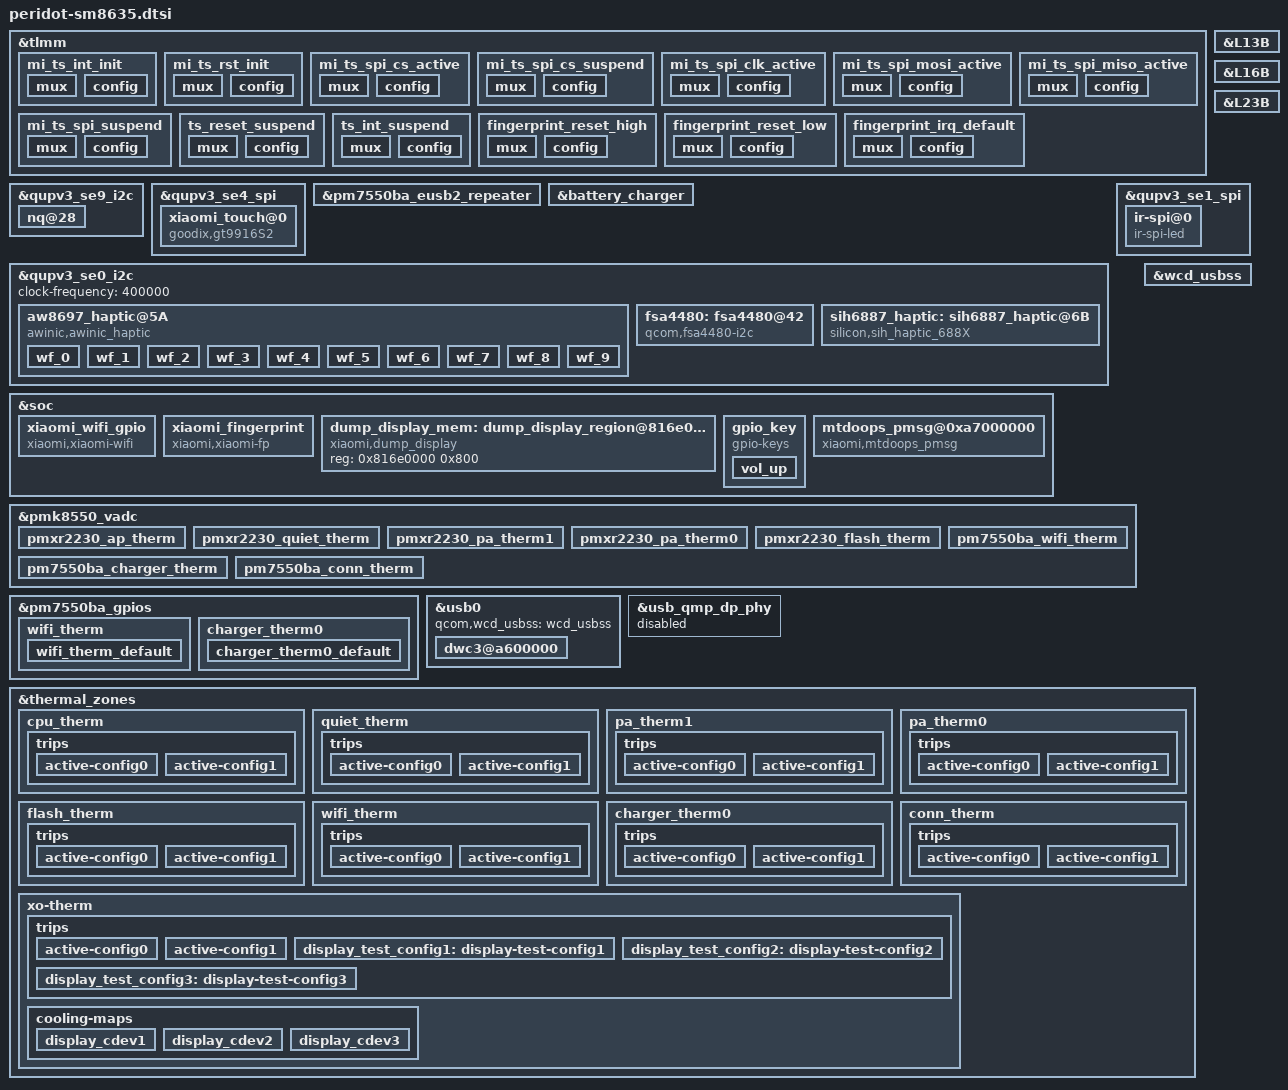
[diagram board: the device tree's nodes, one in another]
#include "cliffs-mtp.dtsi"
#include "cliffs-pm7550ba.dtsi"
#include "peridot-pinctrl.dtsi"

&tlmm {
	mi_ts_int_init: mi_ts_int_init {
		mux {
			pins = "gpio129";
			function = "gpio";
		};

		config {
			pins = "gpio129";
			input-enable;
			bias-disable;
		};
	};
	mi_ts_rst_init: mi_ts_rst_init {
		mux {
			pins = "gpio128";
			function = "gpio";
		};

		config {
			pins = "gpio128";
			drive-strength = <6>;
			bias-disable;
			output-low;
		};
	};

	mi_ts_spi_cs_active: mi_ts_spi_cs_active {
		mux {
			pins = "gpio19";
			function = "qup0_se4_l3";
		};

		config {
			pins = "gpio19";
			drive-strength = <6>;
			bias-disable;
		};
	};

    mi_ts_spi_cs_suspend: mi_ts_spi_cs_suspend {
		mux {
			pins = "gpio19";
			function = "gpio";
		};

		config {
			pins = "gpio19";
			drive-strength = <2>;
			bias-disable;
		};
	};

	mi_ts_spi_clk_active: mi_ts_spi_clk_active {
		mux {
			pins = "gpio18";
			function = "qup0_se4_l2";
		};
		config {
			pins = "gpio18";
			drive-strength = <6>;
			bias-disable;
		};
	};

	mi_ts_spi_mosi_active: mi_ts_spi_mosi_active {
		mux {
			pins = "gpio17";
			function = "qup0_se4_l1";
		};
		config {
			pins = "gpio17";
			drive-strength = <6>;
			bias-disable;
		};
	};


	mi_ts_spi_miso_active: mi_ts_spi_miso_active {
		mux {
			pins = "gpio16";
			function = "qup0_se4_l0";
		};
		config {
			pins = "gpio16";
			drive-strength = <6>;
			bias-disable;
		};
	};


	mi_ts_spi_suspend: mi_ts_spi_suspend {
		mux {
			pins = "gpio16", "gpio17", "gpio18";
			function = "gpio";
		};

		config {
			pins = "gpio16", "gpio17", "gpio18";
			drive-strength = <2>;
			bias-disable;
		};
	};

	ts_reset_suspend: ts_reset_suspend {
		mux {
			pins = "gpio128";
			function = "gpio";
		};

		config {
			pins = "gpio128";
			drive-strength = <6>;
			bias-disable;
		};
	};

	ts_int_suspend: ts_int_suspend {
		mux {
			pins = "gpio129";
			function = "gpio";
		};

		config {
			pins = "gpio129";
			input-enable;
			bias-disable;
		};
	};

    /* FP_RESET_HIGH, state device active*/
    fingerprint_reset_high: fingerprint_reset_high {
        mux {
                pins = "gpio55";
                function = "gpio";
        };
        config {
                pins = "gpio55";
                drive-strength = <2>;
                bias-disable;
                output-high;
        };
    };
    /* FP_RESET_LOW */
    fingerprint_reset_low: fingerprint_reset_low {
        mux {
                pins = "gpio55";
                function = "gpio";
        };
        config {
                pins = "gpio55";
                drive-strength = <2>;
                bias-disable;
                output-low;
        };
    };
    /* FP_INT_N */
    fingerprint_irq_default: fingerprint_irq_default {
        mux {
                pins = "gpio117";
                function = "gpio";
        };
        config {
                pins = "gpio117";
                drive-strength = <2>;
                bias-pull-down;
        };
    };
};

&L13B {
	regulator-min-microvolt = <3300000>;
	regulator-max-microvolt = <3300000>;
	qcom,init-voltage = <3300000>;
};

&L16B {
	regulator-boot-on;
	regulator-always-on;
	regulator-min-microvolt = <3200000>;
	regulator-max-microvolt = <3200000>;
	qcom,init-voltage = <3200000>;
};

&L23B {
	regulator-min-microvolt = <1800000>;
	regulator-max-microvolt = <1800000>;
	qcom,init-voltage = <1800000>;
};

&qupv3_se9_i2c {
	nq@28 {
		qcom,sn-vdd-1p8-supply = <&L5B>;
		qcom,sn-vdd-1p8-voltage = <1200000 1200000>;
		qcom,sn-vdd-1p8-current = <157000>;
	};
};

&qupv3_se4_spi {
	status = "ok";
	qcom,rt;
	pinctrl-0 = <&mi_ts_spi_mosi_active>, <&mi_ts_spi_miso_active>,
				<&mi_ts_spi_clk_active>, <&mi_ts_spi_cs_active>;
	pinctrl-1 = <&mi_ts_spi_suspend>, <&mi_ts_spi_cs_suspend>;
	xiaomi_touch@0 {
		status = "ok";
		compatible = "goodix,gt9916S2", "focaltech,n16t-3683g-spi";
		reg = <0x0>;
		spi-max-frequency = <15000000>;
		interrupt-parent = <&tlmm>;
		interrupts = <129 IRQ_TYPE_LEVEL_LOW>;
		pinctrl-names = "pmx_ts_active", "pmx_ts_suspend";
		pinctrl-0 = <&mi_ts_int_init &mi_ts_rst_init>;
		pinctrl-1 = <&ts_int_suspend &ts_reset_suspend>;

		vdd-supply = <&L23B>;
		avdd-supply = <&L13B>;

		/* parameters for 1st supplier goodix */
		goodix,avdd-name = "avdd";
		goodix,iovdd-name = "vdd";
		goodix,touch-type = "primary";
		goodix,irq-gpio = <&tlmm 129 GPIO_TRANSITORY>;
		goodix,reset-gpio = <&tlmm 128 GPIO_ACTIVE_HIGH>;
		goodix,irq-flags = <IRQ_TYPE_EDGE_FALLING>;
		goodix,panel-max-x = <19520>;
		goodix,panel-max-y = <43392>;
		goodix,panel-max-w = <255>;
		goodix,panel-max-p = <4096>;
		goodix,super-resolution-factor = <16>;
		goodix,firmware-name = "goodix_firmware_peridot_csot.bin";
		goodix,config-name = "goodix_cfg_group_peridot_csot.bin";
		goodix,firmware-name-second = "goodix_firmware_peridot_csot_second.bin";
		goodix,config-name-second = "goodix_cfg_group_peridot_csot_second.bin";

		goodix,ts-id1-gpio = <&tlmm 31 GPIO_ACTIVE_LOW>;
		goodix,ts-id2-gpio = <&tlmm 46 GPIO_ACTIVE_LOW>;

		/* parameters for 2nd supplier focaltech */
		focaltech,avdd-name = "avdd";
		focaltech,iovdd-name = "vdd";
		focaltech,irq-gpio = <&tlmm 129 0x2008>;
		focaltech,reset-gpio = <&tlmm 128 0x00>;
		focaltech,max-touch-number = <10>;
		focaltech,super-resolution-factors = <16>;
		focaltech,display-coords =  <0 0 19520 43392>;
		focaltech,touch-range-array = <1 5 10 15 20>;
		focaltech,touch-def-array = <3 3 3 3>;
		focaltech,touch-expert-array = <10 10 10 10
										20 20 15 10
										20 20 20 10>;
		focaltech,support-fod = <1>;
		focaltech,fod-lx = <504>;
		focaltech,fod-ly = <2332>;
		focaltech,fod-x-size = <210>;
		focaltech,fod-y-size = <210>;

		focaltech,ts-id1-gpio = <&tlmm 31 GPIO_ACTIVE_LOW>;
		focaltech,ts-id2-gpio = <&tlmm 46 GPIO_ACTIVE_LOW>;

		/* parameters for xiaomi_touch */
		mi_tp,game-mode-array =
				<1 0 0 0 0>;  /* MAX MIN DEF SET GET	*/
		mi_tp,active-mode-array =
				<1 0 0 0 0>;  /* MAX MIN DEF SET GET	*/
		mi_tp,tolerance-array =
				<4 0 2 2 2>;  /* MAX MIN DEF SET GET	*/
		mi_tp,up-threshold-array =
				<4 0 3 3 3>;  /* MAX MIN DEF SET GET	*/
		mi_tp,aim-sensitivity-array =
				<4 0 2 2 2>;  /* MAX MIN DEF SET GET	*/
		mi_tp,tap-stability-array =
				<4 0 2 2 2>;  /* MAX MIN DEF SET GET	*/
		mi_tp,edge-filter-array =
				<3 0 2 2 2>;  /* MAX MIN DEF SET GET	*/
		mi_tp,panel-orien-array =
				<3 0 0 0 0>;  /* MAX MIN DEF SET GET	*/
		mi_tp,report-rate-array =
				<3 0 0 0 0>;  /* MAX MIN DEF SET GET	*/
		mi_tp,expert-mode-array =
				<3 1 1 1 1>;  /* MAX MIN DEF SET GET	*/
	};
};

&pm7550ba_eusb2_repeater {
        qcom,param-override-seq =
                <0x00 0x50
                0x0c 0x51
                0x03 0x52
                0x07 0x53
                0x02 0x54
                0x03 0x55
                0x00 0x56
                0x04 0x57
                0x02 0x58
                0x00 0x59
                0x03 0x5a
                0x02 0x5b
                0x00 0x5c>;
		qcom,param-override-seq-factory =
				<0x0 0x50
				0xC 0x51
				0x5 0x52
				0x7 0x53
				0x2 0x54
				0x1 0x55
				0x0 0x56
				0x3 0x57
				0x2 0x58
				0x0 0x59
				0x3 0x5A
				0x2 0x5B>;
		qcom,param-override-seq-host =
				<0x0 0x50
				0xD 0x51
				0x2 0x52
				0x7 0x53
				0x2 0x54
				0x2 0x55
				0x0 0x56
				0x4 0x57
				0x2 0x58
				0x0 0x59
				0x3 0x5A
				0x2 0x5B
				0x0 0x5C>;
};

&battery_charger {
	qcom,shutdown-voltage = <2950>;
	mi,support-shutdown-delay;
};

&qupv3_se0_i2c {
    #address-cells = <1>;
    #size-cells = <0>;
    clock-frequency = <400000>;
    status = "ok";
    aw8697_haptic@5A {
        aw86927_vib_brk_bst_md = <0>;
        aw86927_vib_bst_vol_default = <95>;
        aw86927_vib_bst_vol_ram = <95>;
        aw86927_vib_bst_vol_rtp = <95>;
        aw86927_vib_cont_bemf_set = <2>;
        aw86927_vib_cont_brk_gain = <8>;
        aw86927_vib_cont_brk_time = <8>;
        aw86927_vib_cont_bst_brk_gain = <5>;
        aw86927_vib_cont_drv1_lvl = <127>;
        aw86927_vib_cont_drv1_time = <4>;
        aw86927_vib_cont_drv2_lvl = <54>;
        aw86927_vib_cont_drv2_time = <6>;
        aw86927_vib_cont_drv_width = <106>;
        aw86927_vib_cont_track_margin = <12>;
        aw86927_vib_cont_tset = <6>;
        aw86927_vib_cont_wait_num = <6>;
        aw86927_vib_d2s_gain = <4>;
        aw86927_vib_f0_cali_percen = <7>;
        aw86927_vib_f0_pre = <1700>;
        aw86927_vib_mode = <0>;
        aw86927_vib_trig_config = <0 0 0 1 0 2 0 0 0 0 0 1 0 2 0 0 0 0 0 1 0 2 0 0>;
        aw8697_vib_bemf_config = <0 8 3 248>;
        aw8697_vib_bst_vol_default = <14>;
        aw8697_vib_bst_vol_ram = <14>;
        aw8697_vib_bst_vol_rtp = <14>;
        aw8697_vib_bstdbg = <0x30 0xEB 0xD4 0 0 0>;
        aw8697_vib_cont_drv_lev = <60>;
        aw8697_vib_cont_drv_lvl_ov = <60>;
        aw8697_vib_cont_num_brk = <3>;
        aw8697_vib_cont_td = <0xEF>;
        aw8697_vib_cont_zc_thr = <0x8F8>;
        aw8697_vib_f0_cali_percen = <7>;
        aw8697_vib_f0_coeff = <260>;
        aw8697_vib_f0_pre = <1700>;
        aw8697_vib_f0_trace_parameter = <9 3 1 31>;
        aw8697_vib_mode = <0>;
        aw8697_vib_r_spare = <0x68>;
        aw8697_vib_sw_brake = <0x2C>;
        aw8697_vib_trig_config = <0 1 0 1 2
					   0 1 0 1 2
                       0 1 0 1 2>;
        aw8697_vib_tset = <0x1A>;
        compatible = "awinic,awinic_haptic";
        irq-gpio = <&tlmm 54 0x00>;
        pinctrl-0 = <&awinic_gpio_reset>;
        pinctrl-1 = <&awinic_gpio_reset_output_high>;
        pinctrl-2 = <&awinic_gpio_int>;
        pinctrl-names = "awinic_reset_reset", "awinic_reset_active", "awinic_interrupt_active";
        reg = <0x5A>;
        reset-gpio = <&tlmm 30 0>;
        status = "ok";
        vib_effect_id_boundary = <10>;
        vib_effect_max = <197>;
        vib_rtp_time = <20 20 20 20 20 20 20 20 20000 15000
				15000 20000 25000 15000 30000 25000 20000 20000 20000 20000
                20000 20000 20000 20000 20000 20000 20000 20000 20000 20000
                20000 20000 20000 20000 20000 20000 20000 20000 20000 20000
                20000 20000 20000 20000 20000 20000 20000 20000 20000 20000
                20000 20000 20000 20000 20000 20000 20000 20000 20000 20000
                20000 20000 20000 20000 20000 20000 20000 20000 20000 20000
                20000 20000 20000 20000 20000 20000 20000 20000 20000 20000
                20000 20000 20000 20000 20000 20000 20000 20000 20000 20000
                20000 20000 20000 20000 20000 20000 20000 20000 20000 20000
                20000 20000 20000 20000 20000 20000 20000 20000 20000 20000
                20000 20000 20000 20000 20000 20000 20000 20000 20000 20000
                20000 20000 20000 20000 20000 20000 20000 20000 20000 20000
                20000 20000 20000 20000 20000 20000 20000 20000 20000 20000
                20000 20000 20000 20000 20000 20000 20000 20000 20000 20000
                20000 20000 20000 20000 20000 20000 20000 20000 20000 20000
                20000 20000 20000 20000 20000 20000 20000 20000 20000 20000
                20000 20000 20000 20000 20000>;
        wf_0 {
            qcom,effect-id = <0>;
            qcom,wf-brake-pattern = <02 01 00 00>;
            qcom,wf-pattern = [3E 3E];
            qcom,wf-play-rate-us = <20000>;
            qcom,wf-vmax-mv = <3600>;
        };
        wf_1 {
            qcom,effect-id = <1>;
            qcom,wf-brake-pattern = <03 01 00 00>;
            qcom,wf-pattern = [7E 3E];
            qcom,wf-play-rate-us = <20000>;
            qcom,wf-vmax-mv = <3600>;
        };
        wf_2 {
            qcom,effect-id = <2>;
            qcom,wf-brake-pattern = <02 01 00 00>;
            qcom,wf-pattern = [7E 3E];
            qcom,wf-play-rate-us = <20000>;
            qcom,wf-vmax-mv = <3600>;
        };
        wf_3 {
            qcom,effect-id = <3>;
            qcom,wf-brake-pattern = <02 01 00 00>;
            qcom,wf-pattern = [3E 3E];
            qcom,wf-play-rate-us = <20000>;
            qcom,wf-vmax-mv = <3600>;
        };
        wf_4 {
            qcom,effect-id = <4>;
            qcom,wf-brake-pattern = <02 01 00 00>;
            qcom,wf-pattern = [3E 3E];
            qcom,wf-play-rate-us = <22500>;
            qcom,wf-vmax-mv = <3600>;
        };
        wf_5 {
            qcom,effect-id = <5>;
            qcom,wf-brake-pattern = <03 03 01 00>;
            qcom,wf-pattern = [7E 7E 7E];
            qcom,wf-play-rate-us = <15000>;
            qcom,wf-vmax-mv = <3600>;
        };
        wf_6 {
            qcom,effect-id = <6>;
            qcom,wf-brake-pattern = <02 01 00 00>;
            qcom,wf-pattern = [3E 3E];
            qcom,wf-play-rate-us = <20000>;
            qcom,wf-vmax-mv = <3600>;
        };
        wf_7 {
            qcom,effect-id = <7>;
            qcom,wf-brake-pattern = <02 01 00 00>;
            qcom,wf-pattern = [3E 3E];
            qcom,wf-play-rate-us = <20000>;
            qcom,wf-vmax-mv = <3600>;
        };
        wf_8 {
            qcom,effect-id = <8>;
            qcom,wf-brake-pattern = <02 01 00 00>;
            qcom,wf-pattern = [3E 3E];
            qcom,wf-play-rate-us = <20000>;
            qcom,wf-vmax-mv = <3600>;
        };
        wf_9 {
            qcom,effect-id = <9>;
            qcom,wf-brake-pattern = <02 01 00 00>;
            qcom,wf-pattern = [3E 3E];
            qcom,wf-play-rate-us = <20000>;
            qcom,wf-vmax-mv = <3600>;
        };
    };
    fsa4480: fsa4480@42 {
        compatible = "qcom,fsa4480-i2c";
        mi,lpd-use-sbu_h = <0x1>;
        reg = <0x42>;
        status = "ok";
    };
    sih6887_haptic: sih6887_haptic@6B {
        compatible = "silicon,sih_haptic_688X";
        interrupt = <0x1A 0x1>;
        irq-gpio = <&tlmm 0x36 0x0>;
        lra_name = "0809";
        pinctrl-0 = <&sih_reset_low>;
        pinctrl-1 = <&sih_reset_high>;
        pinctrl-2 = <&sih_interrupt>;
        pinctrl-names = "sih_reset_reset", "sih_reset_active", "sih_interrupt_active";
        reg = <0x6B>;
        reset-gpio = <&tlmm 0x1E 0x0>;
        vib_bst_vol_default = <0x5F>;
        vib_effect_id_boundary = <0xA>;
        vib_effect_max = <0xC5>;
        vib_f0_pre = <0x6A4>;
    };
};


&qupv3_se1_spi {
	status = "ok";
	ir-spi@0 {
		compatible = "ir-spi-led";
		reg = <0>;
		spi-max-frequency = <19200000>;
		status = "ok";
	};
};

&soc {
	xiaomi_wifi_gpio {
		compatible = "xiaomi,xiaomi-wifi";
		gpio = <&tlmm 69 0x00>;
		debounce-time = <30>;
		pinctrl-names = "default";
		pinctrl-0 = <&wifi_ctrl_irq>;
		status = "ok";
	};

    xiaomi_fingerprint {
        compatible = "xiaomi,xiaomi-fp";
        xiaomi,gpio_irq = <&tlmm 117 0x0>;
        fp_goodix-supply = <&L16B>;
        netlink-event = <25>;
        pinctrl-names = "reset_high", "reset_low","irq_default";
        pinctrl-0 = <&fingerprint_reset_high>;
        pinctrl-1 = <&fingerprint_reset_low>;
        pinctrl-2 = <&fingerprint_irq_default>;
        status = "ok";
    };

	dump_display_mem: dump_display_region@816e0000 {
		compatible = "xiaomi,dump_display";
		reg = <0x816e0000  0x800>;
	};

	gpio_key {
		compatible = "gpio-keys";
		label = "gpio-keys";
		pinctrl-names = "default";
		pinctrl-0 = <&key_vol_up_default>;
		vol_up {
			label = "volume_up";
			gpios = <&pmxr2230_gpios 6 GPIO_ACTIVE_LOW>;
			linux,input-type = <1>;
			linux,code = <KEY_VOLUMEUP>;
			gpio-key,wakeup;
			debounce-interval = <32>;
			linux,can-disable;
		};
	};

	mtdoops_pmsg@0xa7000000 {
		compatible = "xiaomi,mtdoops_pmsg";
		reg = <0xa7000000 0x400000>;
		console-size = <0x200000>;
		pmsg-size = <0x200000>;
	};
};

&pmk8550_vadc {
	pinctrl-names = "default";
	pinctrl-0 = <&charger_therm0_default>, <&wifi_therm_default>;

	pmxr2230_ap_therm {
		reg = <PMXR2230_ADC5_GEN3_AMUX_THM2_100K_PU>;
		label = "pmxr2230_ap_therm";
		qcom,ratiometric;
		qcom,hw-settle-time = <200>;
		qcom,pre-scaling = <1 1>;
		qcom,adc-tm-type = <1>;
	};

	pmxr2230_quiet_therm {
		reg = <PMXR2230_ADC5_GEN3_AMUX_THM4_100K_PU>;
		label = "pmxr2230_quiet_therm";
		qcom,ratiometric;
		qcom,hw-settle-time = <200>;
		qcom,pre-scaling = <1 1>;
		qcom,adc-tm-type = <1>;
	};

	pmxr2230_pa_therm1 {
		reg = <PMXR2230_ADC5_GEN3_AMUX_THM3_100K_PU>;
		label = "pmxr2230_pa_therm1";
		qcom,ratiometric;
		qcom,hw-settle-time = <200>;
		qcom,pre-scaling = <1 1>;
		qcom,adc-tm-type = <1>;
	};

	pmxr2230_pa_therm0 {
		reg = <PMXR2230_ADC5_GEN3_AMUX_THM1_100K_PU>;
		label = "pmxr2230_pa_therm0";
		qcom,ratiometric;
		qcom,hw-settle-time = <200>;
		qcom,pre-scaling = <1 1>;
		qcom,adc-tm-type = <1>;
	};

	pmxr2230_flash_therm {
		reg = <PMXR2230_ADC5_GEN3_AMUX_THM5_100K_PU>;
		label = "pmxr2230_flash_therm";
		qcom,ratiometric;
		qcom,hw-settle-time = <200>;
		qcom,pre-scaling = <1 1>;
		qcom,adc-tm-type = <1>;
	};

	pm7550ba_wifi_therm {
		reg = <PM7550BA_ADC5_GEN3_AMUX3_GPIO3_100K_PU>;
		label = "pm7550ba_wifi_therm";
		qcom,ratiometric;
		qcom,hw-settle-time = <200>;
		qcom,pre-scaling = <1 1>;
		qcom,adc-tm-type = <1>;
	};

	pm7550ba_charger_therm {
		reg = <PM7550BA_ADC5_GEN3_AMUX_THM6_GPIO6_100K_PU>;
		label = "pm7550ba_charger_therm";
		qcom,ratiometric;
		qcom,hw-settle-time = <200>;
		qcom,pre-scaling = <1 1>;
		qcom,adc-tm-type = <1>;
	};

	pm7550ba_conn_therm {
		reg = <PM7550BA_ADC5_GEN3_AMUX_THM4_USB_THERM_100K_PU>;
		label = "pm7550ba_conn_therm";
		qcom,ratiometric;
		qcom,hw-settle-time = <200>;
		qcom,pre-scaling = <1 1>;
		qcom,adc-tm-type = <1>;
	};
};

&pm7550ba_gpios{
	wifi_therm {
		wifi_therm_default:wifi_therm_default {
		pins = "gpio3";
		bias-high-impedance;
		};
	};
};

&pm7550ba_gpios{
	charger_therm0 {
		charger_therm0_default:charger_therm0_default {
		pins = "gpio6";
		bias-high-impedance;
		};
	};
};

&usb0 {
        qcom,wcd_usbss = <&wcd_usbss>;
};

&wcd_usbss {
        wcd-equ-bw-settings = <0x8>;
        wcd-equ-bw-settings-host = <0x8>;
};

&usb_qmp_dp_phy {
	status = "disabled";
};

&usb0 {
	dwc3@a600000 {
		usb-phy = <&eusb2_phy0>, <&usb_nop_phy>;
		maximum-speed = "high-speed";
 	};
};

&thermal_zones {
	cpu_therm {
		polling-delay-passive = <0>;
		polling-delay = <0>;
		thermal-sensors = <&pmk8550_vadc PMXR2230_ADC5_GEN3_AMUX_THM2_100K_PU>;
		trips {
			active-config0 {
				temperature = <125000>;
				hysteresis = <1000>;
				type = "passive";
			};

			active-config1 {
				temperature = <125000>;
				hysteresis = <1000>;
				type = "passive";
			};
		};
	};

	quiet_therm {
		polling-delay-passive = <0>;
		polling-delay = <0>;
		thermal-sensors = <&pmk8550_vadc PMXR2230_ADC5_GEN3_AMUX_THM4_100K_PU>;
		trips {
			active-config0 {
				temperature = <125000>;
				hysteresis = <1000>;
				type = "passive";
			};

			active-config1 {
				temperature = <125000>;
				hysteresis = <1000>;
				type = "passive";
			};
		};
	};

	pa_therm1 {
		polling-delay-passive = <0>;
		polling-delay = <0>;
		thermal-sensors = <&pmk8550_vadc PMXR2230_ADC5_GEN3_AMUX_THM3_100K_PU>;
		trips {
			active-config0 {
				temperature = <125000>;
				hysteresis = <1000>;
				type = "passive";
			};

			active-config1 {
				temperature = <125000>;
				hysteresis = <1000>;
				type = "passive";
			};
		};
	};

	pa_therm0 {
		polling-delay-passive = <0>;
		polling-delay = <0>;
		thermal-sensors = <&pmk8550_vadc PMXR2230_ADC5_GEN3_AMUX_THM1_100K_PU>;
		trips {
			active-config0 {
				temperature = <125000>;
				hysteresis = <1000>;
				type = "passive";
			};

			active-config1 {
				temperature = <125000>;
				hysteresis = <1000>;
				type = "passive";
			};
		};
	};

	flash_therm {
		polling-delay-passive = <0>;
		polling-delay = <0>;
		thermal-sensors = <&pmk8550_vadc PMXR2230_ADC5_GEN3_AMUX_THM5_100K_PU>;
		trips {
			active-config0 {
				temperature = <125000>;
				hysteresis = <1000>;
				type = "passive";
			};

			active-config1 {
				temperature = <125000>;
				hysteresis = <1000>;
				type = "passive";
			};
		};
	};

	wifi_therm {
		polling-delay-passive = <0>;
		polling-delay = <0>;
		thermal-sensors = <&pmk8550_vadc PM7550BA_ADC5_GEN3_AMUX3_GPIO3_100K_PU>;
		trips {
			active-config0 {
				temperature = <125000>;
				hysteresis = <1000>;
				type = "passive";
			};

			active-config1 {
				temperature = <125000>;
				hysteresis = <1000>;
				type = "passive";
			};
		};
	};

	charger_therm0 {
		polling-delay-passive = <0>;
		polling-delay = <0>;
		thermal-sensors = <&pmk8550_vadc PM7550BA_ADC5_GEN3_AMUX_THM6_GPIO6_100K_PU>;
		trips {
			active-config0 {
				temperature = <125000>;
				hysteresis = <1000>;
				type = "passive";
			};

			active-config1 {
				temperature = <125000>;
				hysteresis = <1000>;
				type = "passive";
			};
		};
	};
	conn_therm {
		polling-delay-passive = <0>;
		polling-delay = <0>;
		thermal-sensors = <&pmk8550_vadc PM7550BA_ADC5_GEN3_AMUX_THM4_USB_THERM_100K_PU>;
		trips {
			active-config0 {
				temperature = <125000>;
				hysteresis = <1000>;
				type = "passive";
			};

			active-config1 {
				temperature = <125000>;
				hysteresis = <1000>;
				type = "passive";
			};
		};
	};
	xo-therm {
		polling-delay-passive = <0>;
		polling-delay = <0>;
		thermal-sensors = <&pmk8550_vadc PMK8550_ADC5_GEN3_AMUX_THM1_XO_THERM_100K_PU>;
		trips {
			active-config0 {
				temperature = <125000>;
				hysteresis = <1000>;
				type = "passive";
			};

			active-config1 {
				temperature = <125000>;
				hysteresis = <1000>;
				type = "passive";
			};

			display_test_config1: display-test-config1 {
				temperature = <125000>;
				hysteresis = <1000>;
				type = "passive";
			};

			display_test_config2: display-test-config2 {
				temperature = <125000>;
				hysteresis = <1000>;
				type = "passive";
			};

			display_test_config3: display-test-config3 {
				temperature = <125000>;
				hysteresis = <1000>;
				type = "passive";
			};
		};
        cooling-maps {
            display_cdev1 {
                cooling-device = <&display_fps 0x1 0x1>;
                trip = <&display_test_config1>;
            };
            display_cdev2 {
                cooling-device = <&display_fps 0x2 0x2>;
                trip = <&display_test_config2>;
            };
            display_cdev3 {
                cooling-device = <&display_fps 0x3 0x3>;
                trip = <&display_test_config3>;
            };
        };
	};
};
